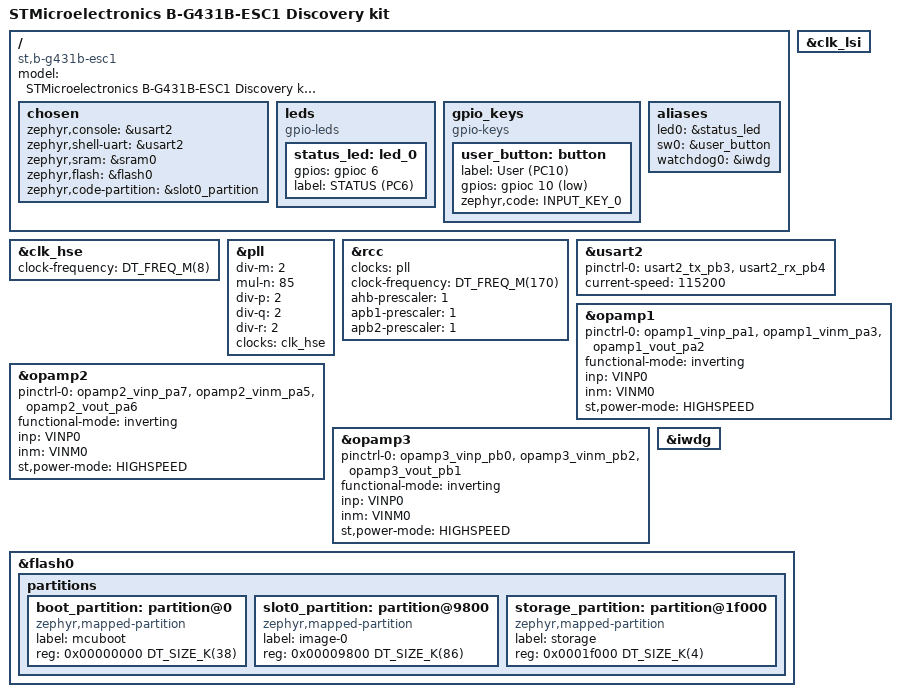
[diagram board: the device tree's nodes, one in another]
/*
 * SPDX-License-Identifier: Apache-2.0
 *
 * STMicroelectronics B-G431B-ESC1 Discovery kit (STM32G431CBU6).
 *
 * Pin assignment: UM2516 Rev 4, Table 4 "Main board STM32G431CB pinout for
 * motor control". Current sense network (3 mOhm shunts, OPAMP PGA with the
 * inverting input as bias, effective gain -9.14) and bus voltage divider
 * (18k / (18k + 169k)) as used by ST MCSDK, NuttX and SimpleFOC for this kit.
 */

/dts-v1/;
#include <st/g4/stm32g431Xb.dtsi>
#include <st/g4/stm32g431c(6-8-b)ux-pinctrl.dtsi>
#include <zephyr/dt-bindings/input/input-event-codes.h>

/ {
	model = "STMicroelectronics B-G431B-ESC1 Discovery kit";
	compatible = "st,b-g431b-esc1";

	chosen {
		zephyr,console = &usart2;
		zephyr,shell-uart = &usart2;
		zephyr,sram = &sram0;
		zephyr,flash = &flash0;
		zephyr,code-partition = &slot0_partition;
	};

	leds: leds {
		compatible = "gpio-leds";

		status_led: led_0 {
			gpios = <&gpioc 6 GPIO_ACTIVE_HIGH>;
			label = "STATUS (PC6)";
		};
	};

	gpio_keys {
		compatible = "gpio-keys";

		user_button: button {
			label = "User (PC10)";
			gpios = <&gpioc 10 GPIO_ACTIVE_LOW>;
			zephyr,code = <INPUT_KEY_0>;
		};
	};

	aliases {
		led0 = &status_led;
		sw0 = &user_button;
		watchdog0 = &iwdg;
	};
};

&clk_lsi {
	status = "okay";
};

/* 8 MHz crystal on PF0/PF1 (UM2516 Table 4) */
&clk_hse {
	clock-frequency = <DT_FREQ_M(8)>;
	status = "okay";
};

/* 8 MHz / 2 * 85 / 2 = 170 MHz */
&pll {
	div-m = <2>;
	mul-n = <85>;
	div-p = <2>;
	div-q = <2>;
	div-r = <2>;
	clocks = <&clk_hse>;
	status = "okay";
};

&rcc {
	clocks = <&pll>;
	clock-frequency = <DT_FREQ_M(170)>;
	ahb-prescaler = <1>;
	apb1-prescaler = <1>;
	apb2-prescaler = <1>;
};

/* USART2: J3 pads and the ST-LINK/V2-1 Virtual COM Port */
&usart2 {
	pinctrl-0 = <&usart2_tx_pb3 &usart2_rx_pb4>;
	pinctrl-names = "default";
	current-speed = <115200>;
	status = "okay";
};

/*
 * Phase current amplifiers U, V, W: PGA, gain 16 / -15, VINM0 used as bias
 * input, output on the pin (OPx_OUT) for the ADC. The gain is set at run time
 * with opamp_set_gain() (OPAMP_GAIN_15 / OPAMP_GAIN_16).
 */
&opamp1 {
	pinctrl-0 = <&opamp1_vinp_pa1 &opamp1_vinm_pa3 &opamp1_vout_pa2>;
	pinctrl-names = "default";
	functional-mode = "inverting";
	inp = "VINP0";
	inm = "VINM0";
	st,power-mode = "HIGHSPEED";
	status = "okay";
};

&opamp2 {
	pinctrl-0 = <&opamp2_vinp_pa7 &opamp2_vinm_pa5 &opamp2_vout_pa6>;
	pinctrl-names = "default";
	functional-mode = "inverting";
	inp = "VINP0";
	inm = "VINM0";
	st,power-mode = "HIGHSPEED";
	status = "okay";
};

&opamp3 {
	pinctrl-0 = <&opamp3_vinp_pb0 &opamp3_vinm_pb2 &opamp3_vout_pb1>;
	pinctrl-names = "default";
	functional-mode = "inverting";
	inp = "VINP0";
	inm = "VINM0";
	st,power-mode = "HIGHSPEED";
	status = "okay";
};

&iwdg {
	status = "okay";
};

/*
 * 128 KiB of flash, 2 KiB pages:
 *
 *   boot_partition     MCUboot (sysbuild, docs/firmware-update.md)
 *   slot0_partition    application, signed; serial recovery writes it
 *   storage_partition  NVS: EEPROM area of the emulated DYNAMIXEL
 */
&flash0 {
	partitions {
		#address-cells = <1>;
		#size-cells = <1>;
		ranges;

		boot_partition: partition@0 {
			compatible = "zephyr,mapped-partition";
			label = "mcuboot";
			reg = <0x00000000 DT_SIZE_K(38)>;
		};

		slot0_partition: partition@9800 {
			compatible = "zephyr,mapped-partition";
			label = "image-0";
			reg = <0x00009800 DT_SIZE_K(86)>;
		};

		/* 2 x 2 KiB flash pages at the end of the 128 KiB of flash */
		storage_partition: partition@1f000 {
			compatible = "zephyr,mapped-partition";
			label = "storage";
			reg = <0x0001f000 DT_SIZE_K(4)>;
		};
	};
};
